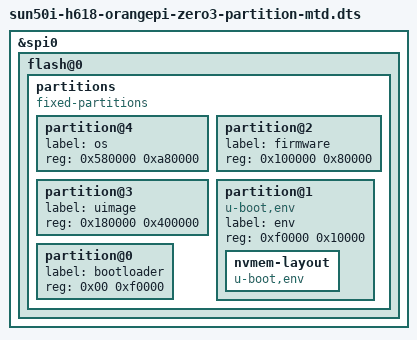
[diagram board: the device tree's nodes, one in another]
/dts-v1/;
/plugin/;

/ {
	fragment@0 {
		compatible = "xunlong,orangepi-zero3";
		target = <&spi0>;
		__overlay__ {
			flash@0 {
				partitions {
					compatible = "fixed-partitions";
					#address-cells = <0x01>;
					#size-cells = <0x01>;
					partition@4 {
						label = "os";
						reg = <0x580000 0xa80000>;
					};
					partition@3 {
						label = "uimage";
						reg = <0x180000 0x400000>;
					};
					partition@2 {
						label = "firmware";
						reg = <0x100000 0x80000>;
					};
					partition@1 {
						compatible = "u-boot,env";
						label = "env";
						reg = <0xf0000 0x10000>;
						nvmem-layout {
							compatible = "u-boot,env";
						};
					};
					partition@0 {
						label = "bootloader";
						reg = <0x00 0xf0000>;
					};
				};
			};
		};
	};
};
